# STM32F102 register map
File version: 1.2
CPU: CM3 r1p1, little endian, no MPU, no FPU, 4 interrupt priority bits
Registers are 32-bit, read-write, reset 0x0 unless marked. A register's access mark holds for its fields unless they carry their own. Offsets are from the block's base; [hi:lo] are bit positions; {n}, {i} and the like mark numbered series.

## UART5 — Universal asynchronous receiver transmitter
Base 0x40005000
Same registers: UART4 0x40004C00
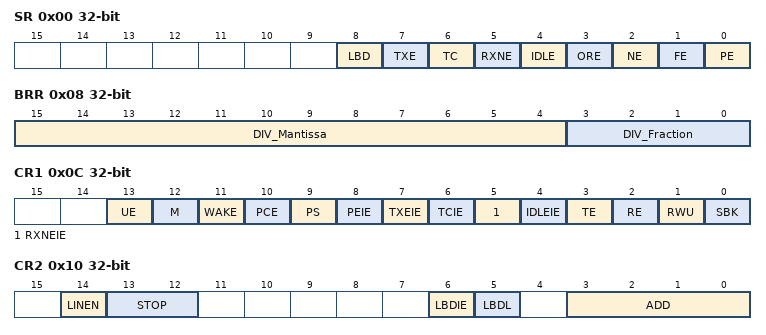
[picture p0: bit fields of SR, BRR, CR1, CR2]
0x00 SR access per field — Status register
  [8] LBD rw — LIN break detection flag
  [7] TXE ro — Transmit data register empty
  [6] TC rw — Transmission complete
  [5] RXNE rw — Read data register not empty
  [4] IDLE ro — IDLE line detected
  [3] ORE ro — Overrun error
  [2] NE ro — Noise error flag
  [1] FE ro — Framing error
  [0] PE ro — Parity error
0x04 DR — Data register
  [8:0] DR
0x08 BRR — Baud rate register
  [15:4] DIV_Mantissa, [3:0] DIV_Fraction
0x0C CR1 — Control register 1
  [13] UE — USART enable
  [12] M — Word length
  [11] WAKE — Wakeup method
  [10] PCE — Parity control enable
  [9] PS — Parity selection
  [8] PEIE — PE interrupt enable
  [7] TXEIE — TXE interrupt enable
  [6] TCIE — Transmission complete interrupt enable
  [5] RXNEIE — RXNE interrupt enable
  [4] IDLEIE — IDLE interrupt enable
  [3] TE — Transmitter enable
  [2] RE — Receiver enable
  [1] RWU — Receiver wakeup
  [0] SBK — Send break
0x10 CR2 — Control register 2
  [14] LINEN — LIN mode enable
  [13:12] STOP — STOP bits
  [6] LBDIE — LIN break detection interrupt enable
  [5] LBDL — lin break detection length
  [3:0] ADD — Address of the USART node
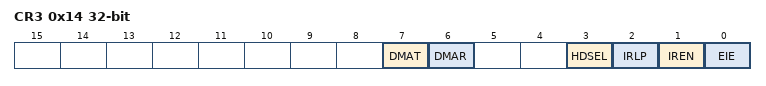
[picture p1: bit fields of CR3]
0x14 CR3 — Control register 3
  [7] DMAT — DMA enable transmitter
  [6] DMAR — DMA enable receiver
  [3] HDSEL — Half-duplex selection
  [2] IRLP — IrDA low-power
  [1] IREN — IrDA mode enable
  [0] EIE — Error interrupt enable

## TIM6 — Basic timer
Base 0x40001000
Same registers: TIM7 0x40001400
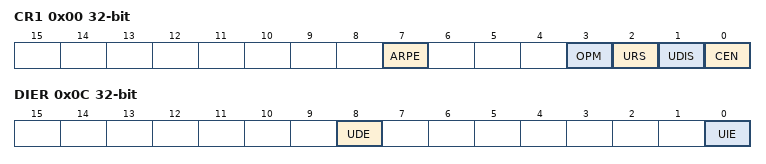
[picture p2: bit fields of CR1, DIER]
0x00 CR1 — control register 1
  [7] ARPE — Auto-reload preload enable
  [3] OPM — One-pulse mode
  [2] URS — Update request source
  [1] UDIS — Update disable
  [0] CEN — Counter enable
0x04 CR2 — control register 2
  [6:4] MMS — Master mode selection
0x0C DIER — DMA/Interrupt enable register
  [8] UDE — Update DMA request enable
  [0] UIE — Update interrupt enable
0x10 SR — status register
  [0] UIF — Update interrupt flag
0x14 EGR wo — event generation register
  [0] UG — Update generation
0x24 CNT — counter
  [15:0] CNT — Low counter value
0x28 PSC — prescaler
  [15:0] PSC — Prescaler value
0x2C ARR — auto-reload register
  [15:0] ARR — Low Auto-reload value

## NVIC — Nested Vectored Interrupt Controller
Base 0xE000E100
0x00 ISER0 — Interrupt Set-Enable Register
  [31:0] SETENA
0x04 ISER1 — Interrupt Set-Enable Register
  [31:0] SETENA
0x80 ICER0 — Interrupt Clear-Enable Register
  [31:0] CLRENA
0x84 ICER1 — Interrupt Clear-Enable Register
  [31:0] CLRENA
0x100 ISPR0 — Interrupt Set-Pending Register
  [31:0] SETPEND
0x104 ISPR1 — Interrupt Set-Pending Register
  [31:0] SETPEND
0x180 ICPR0 — Interrupt Clear-Pending Register
  [31:0] CLRPEND
0x184 ICPR1 — Interrupt Clear-Pending Register
  [31:0] CLRPEND
0x200 IABR0 ro — Interrupt Active Bit Register
  [31:0] ACTIVE
0x204 IABR1 ro — Interrupt Active Bit Register
  [31:0] ACTIVE
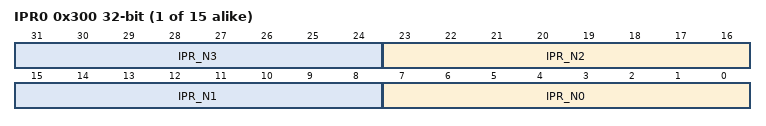
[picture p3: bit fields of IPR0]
{0x300+4i} IPR{i} (i=0..14) — Interrupt Priority Register
  [8n+7:8n] IPR_N{n} (n=0..3)

## MPU — Memory protection unit
Base 0xE000ED90
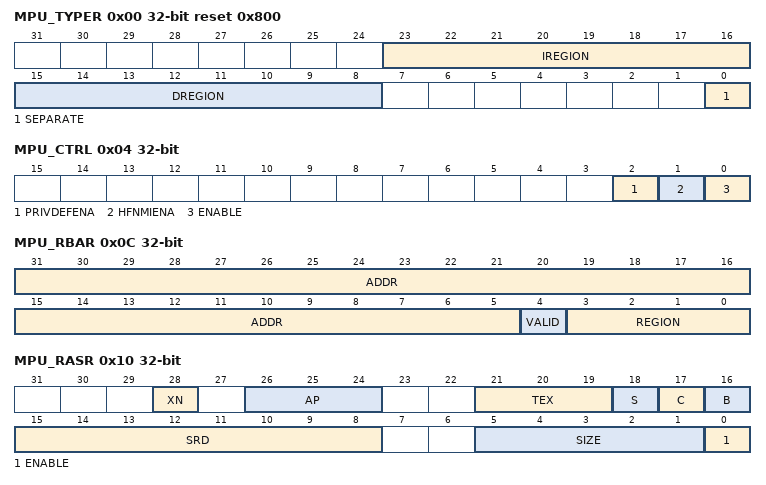
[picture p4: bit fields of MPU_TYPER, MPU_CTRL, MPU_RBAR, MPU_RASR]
0x00 MPU_TYPER ro reset 0x800 — MPU type register
  [23:16] IREGION — Number of MPU instruction regions
  [15:8] DREGION — Number of MPU data regions
  [0] SEPARATE — Separate flag
0x04 MPU_CTRL ro — MPU control register
  [2] PRIVDEFENA — Enable priviliged software access to default memory map
  [1] HFNMIENA — Enables the operation of MPU during hard fault
  [0] ENABLE — Enables the MPU
0x08 MPU_RNR — MPU region number register
  [7:0] REGION — MPU region
0x0C MPU_RBAR — MPU region base address register
  [31:5] ADDR — Region base address field
  [4] VALID — MPU region number valid
  [3:0] REGION — MPU region field
0x10 MPU_RASR — MPU region attribute and size register
  [28] XN — Instruction access disable bit
  [26:24] AP — Access permission
  [21:19] TEX — memory attribute
  [18] S — Shareable memory attribute
  [17] C — memory attribute
  [16] B — memory attribute
  [15:8] SRD — Subregion disable bits
  [5:1] SIZE — Size of the MPU protection region
  [0] ENABLE — Region enable bit.

## SCB_ACTRL — System control block ACTLR
Base 0xE000E008
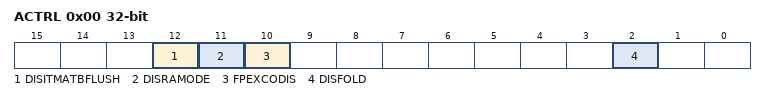
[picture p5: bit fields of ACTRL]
0x00 ACTRL — Auxiliary control register
  [12] DISITMATBFLUSH, [11] DISRAMODE, [10] FPEXCODIS, [2] DISFOLD

## NVIC_STIR — Nested vectored interrupt controller
Base 0xE000EF00
0x00 STIR — Software trigger interrupt register
  [8:0] INTID — Software generated interrupt ID

## STK — SysTick timer
Base 0xE000E010
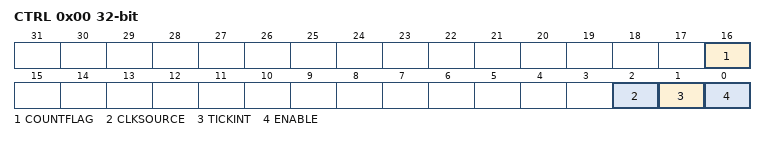
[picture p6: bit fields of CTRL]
0x00 CTRL — SysTick control and status register
  [16] COUNTFLAG
  [2] CLKSOURCE — Clock source selection
  [1] TICKINT — SysTick exception request enable
  [0] ENABLE — Counter enable
0x04 LOAD_ — SysTick reload value register
  [23:0] RELOAD — RELOAD value
0x08 VAL — SysTick current value register
  [23:0] CURRENT — Current counter value
0x0C CALIB — SysTick calibration value register
  [23:0] TENMS — Calibration value
